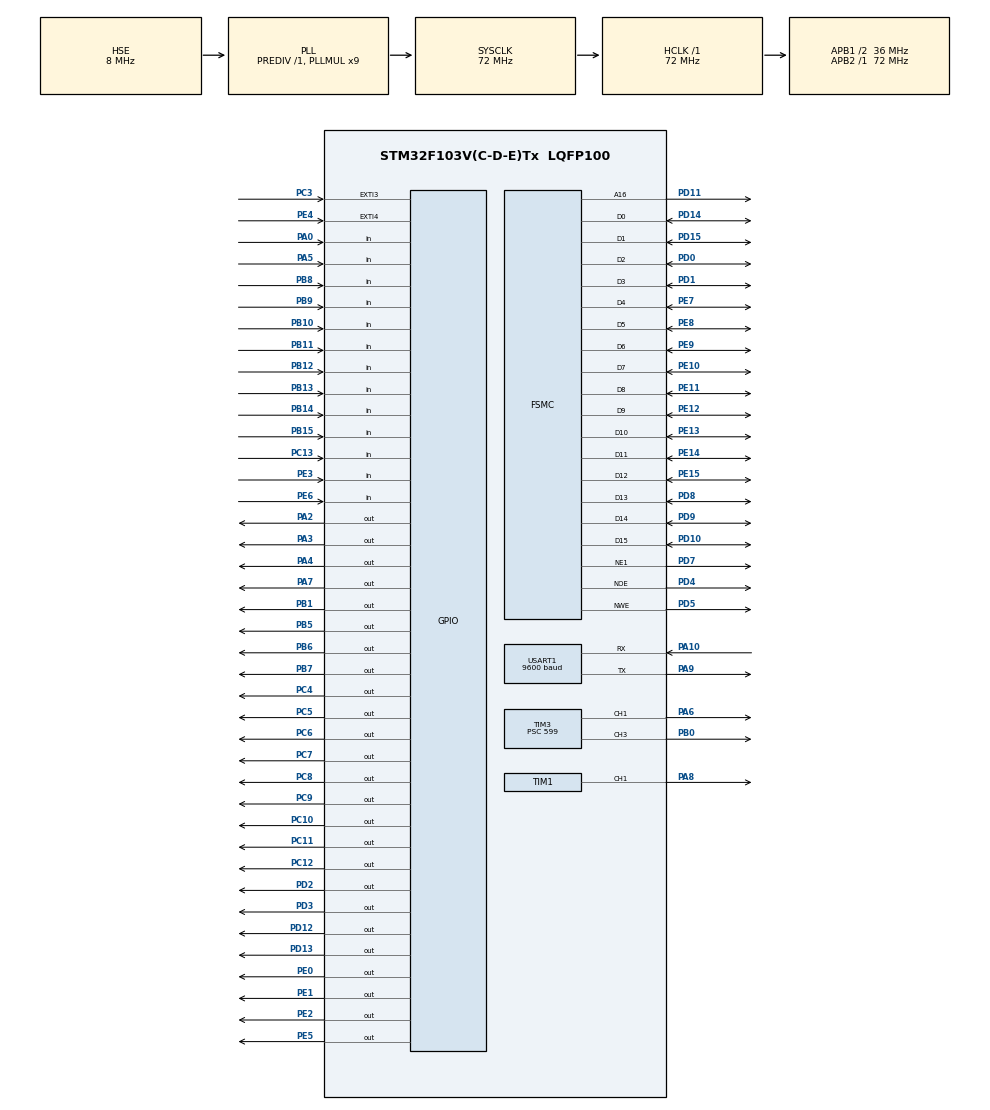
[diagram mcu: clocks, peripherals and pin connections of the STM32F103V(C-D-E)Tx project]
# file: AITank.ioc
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Mcu.Family=STM32F1
Mcu.Name=STM32F103V(C-D-E)Tx
Mcu.Package=LQFP100
NVIC.EXTI3_IRQn=true\:0\:0\:false\:false\:true\:true\:true\:true
NVIC.EXTI4_IRQn=true\:0\:0\:false\:false\:true\:true\:true\:true
NVIC.PriorityGroup=NVIC_PRIORITYGROUP_4
NVIC.TIM2_IRQn=true\:0\:0\:false\:false\:true\:true\:true\:true
OSC_IN.Mode=HSE-External-Oscillator
OSC_IN.Signal=RCC_OSC_IN
OSC_OUT.Mode=HSE-External-Oscillator
OSC_OUT.Signal=RCC_OSC_OUT
PA0-WKUP.Signal=GPIO_Input
PA10.Mode=Asynchronous
PA10.Signal=USART1_RX
PA13.Mode=Serial_Wire
PA13.Signal=SYS_JTMS-SWDIO
PA14.Mode=Serial_Wire
PA14.Signal=SYS_JTCK-SWCLK
PA2.GPIO_Speed=GPIO_SPEED_FREQ_HIGH
PA2.Signal=GPIO_Output
PA3.GPIO_Speed=GPIO_SPEED_FREQ_HIGH
PA3.Signal=GPIO_Output
PA4.GPIO_Speed=GPIO_SPEED_FREQ_HIGH
PA4.PinState=GPIO_PIN_RESET
PA4.Signal=GPIO_Output
PA5.Signal=GPIO_Input
PA6.GPIO_Speed=GPIO_SPEED_FREQ_LOW
PA6.Signal=S_TIM3_CH1
PA7.Signal=GPIO_Output
PA8.Signal=S_TIM1_CH1
PA9.Mode=Asynchronous
PA9.Signal=USART1_TX
PB0.Signal=S_TIM3_CH3
PB1.GPIO_Speed=GPIO_SPEED_FREQ_HIGH
PB1.PinState=GPIO_PIN_SET
PB1.Signal=GPIO_Output
PB10.Signal=GPIO_Input
PB11.Signal=GPIO_Input
PB12.Signal=GPIO_Input
PB13.Signal=GPIO_Input
PB14.Signal=GPIO_Input
PB15.Signal=GPIO_Input
PB5.GPIO_Speed=GPIO_SPEED_FREQ_HIGH
PB5.PinState=GPIO_PIN_SET
PB5.Signal=GPIO_Output
PB6.GPIO_Speed=GPIO_SPEED_FREQ_HIGH
PB6.Signal=GPIO_Output
PB7.GPIO_Speed=GPIO_SPEED_FREQ_HIGH
PB7.Signal=GPIO_Output
PB8.Signal=GPIO_Input
PB9.Signal=GPIO_Input
PC10.GPIO_Speed=GPIO_SPEED_FREQ_HIGH
PC10.Signal=GPIO_Output
PC11.GPIO_Speed=GPIO_SPEED_FREQ_HIGH
PC11.Signal=GPIO_Output
PC12.GPIO_Speed=GPIO_SPEED_FREQ_HIGH
PC12.Signal=GPIO_Output
PC13-TAMPER-RTC.Signal=GPIO_Input
PC14-OSC32_IN.Mode=LSE-External-Oscillator
PC14-OSC32_IN.Signal=RCC_OSC32_IN
PC15-OSC32_OUT.Mode=LSE-External-Oscillator
PC15-OSC32_OUT.Signal=RCC_OSC32_OUT
PC3.GPIO_ModeDefaultEXTI=GPIO_MODE_IT_FALLING
PC3.Signal=GPXTI3
PC4.GPIO_Speed=GPIO_SPEED_FREQ_HIGH
PC4.Signal=GPIO_Output
PC5.GPIO_Speed=GPIO_SPEED_FREQ_HIGH
PC5.Signal=GPIO_Output
PC6.GPIO_ModeDefaultOutputPP=GPIO_MODE_OUTPUT_OD
PC6.GPIO_PuPd=GPIO_NOPULL
PC6.GPIO_Speed=GPIO_SPEED_FREQ_HIGH
PC6.Signal=GPIO_Output
PC7.GPIO_ModeDefaultOutputPP=GPIO_MODE_OUTPUT_OD
PC7.GPIO_PuPd=GPIO_NOPULL
PC7.GPIO_Speed=GPIO_SPEED_FREQ_HIGH
PC7.Signal=GPIO_Output
PC8.GPIO_Speed=GPIO_SPEED_FREQ_HIGH
PC8.Signal=GPIO_Output
PC9.GPIO_Speed=GPIO_SPEED_FREQ_HIGH
PC9.Signal=GPIO_Output
PD0.Mode=16b-d1
PD0.Signal=FSMC_D2
PD1.Mode=16b-d1
PD1.Signal=FSMC_D3
PD10.Mode=16b-d1
PD10.Signal=FSMC_D15
PD11.Mode=A16_1
PD11.Signal=FSMC_A16
PD12.GPIO_Speed=GPIO_SPEED_FREQ_HIGH
PD12.Signal=GPIO_Output
PD13.GPIO_Speed=GPIO_SPEED_FREQ_HIGH
PD13.Signal=GPIO_Output
PD14.Mode=16b-d1
PD14.Signal=FSMC_D0
PD15.Mode=16b-d1
PD15.Signal=FSMC_D1
PD2.GPIO_Speed=GPIO_SPEED_FREQ_HIGH
PD2.Signal=GPIO_Output
PD3.GPIO_Speed=GPIO_SPEED_FREQ_HIGH
PD3.Signal=GPIO_Output
PD4.Mode=Lcd1
PD4.Signal=FSMC_NOE
PD5.Mode=Lcd1
PD5.Signal=FSMC_NWE
PD7.Mode=NorPsramChipSelect1_1
PD7.Signal=FSMC_NE1
PD8.Mode=16b-d1
PD8.Signal=FSMC_D13
PD9.Mode=16b-d1
PD9.Signal=FSMC_D14
PE0.GPIO_Speed=GPIO_SPEED_FREQ_HIGH
PE0.Signal=GPIO_Output
PE1.Signal=GPIO_Output
PE10.Mode=16b-d1
PE10.Signal=FSMC_D7
PE11.Mode=16b-d1
PE11.Signal=FSMC_D8
PE12.Mode=16b-d1
PE12.Signal=FSMC_D9
PE13.Mode=16b-d1
PE13.Signal=FSMC_D10
PE14.Mode=16b-d1
PE14.Signal=FSMC_D11
PE15.Mode=16b-d1
PE15.Signal=FSMC_D12
PE2.GPIO_Speed=GPIO_SPEED_FREQ_HIGH
PE2.Signal=GPIO_Output
PE3.GPIO_PuPd=GPIO_PULLUP
PE3.Signal=GPIO_Input
PE4.GPIO_ModeDefaultEXTI=GPIO_MODE_IT_FALLING
PE4.GPIO_PuPd=GPIO_PULLUP
PE4.Signal=GPXTI4
PE5.Signal=GPIO_Output
PE6.Signal=GPIO_Input
PE7.Mode=16b-d1
PE7.Signal=FSMC_D4
PE8.Mode=16b-d1
PE8.Signal=FSMC_D5
PE9.Mode=16b-d1
PE9.Signal=FSMC_D6
ProjectManager.HeapSize=0x200
ProjectManager.StackSize=0x400
ProjectManager.TargetToolchain=STM32CubeIDE
RCC.AHBFreq_Value=72000000
RCC.APB1CLKDivider=RCC_HCLK_DIV2
RCC.APB1Freq_Value=36000000
RCC.APB1TimFreq_Value=72000000
RCC.APB2Freq_Value=72000000
RCC.APB2TimFreq_Value=72000000
RCC.HCLKFreq_Value=72000000
RCC.PLLMUL=RCC_PLL_MUL9
RCC.PLLSourceVirtual=RCC_PLLSOURCE_HSE
RCC.SYSCLKFreq_VALUE=72000000
RCC.SYSCLKSource=RCC_SYSCLKSOURCE_PLLCLK
RCC.USBFreq_Value=72000000
SH.S_TIM1_CH1.0=TIM1_CH1,PWM Generation1 CH1
SH.S_TIM3_CH1.0=TIM3_CH1,PWM Generation1 CH1
SH.S_TIM3_CH3.0=TIM3_CH3,PWM Generation3 CH3
TIM1.Channel-PWM\ Generation1\ CH1=TIM_CHANNEL_1
TIM1.Period=1000-1
TIM1.Prescaler=1400-1
TIM2.Period=57
TIM2.Prescaler=72
TIM2.TIM_MasterOutputTrigger=TIM_TRGO_UPDATE
TIM3.Channel-PWM\ Generation1\ CH1=TIM_CHANNEL_1
TIM3.Channel-PWM\ Generation3\ CH3=TIM_CHANNEL_3
TIM3.Period=1199
TIM3.Prescaler=599
TIM3.Pulse-PWM\ Generation1\ CH1=0
TIM3.TIM_MasterOutputTrigger=TIM_TRGO_RESET
TIM3.TIM_MasterSlaveMode=TIM_MASTERSLAVEMODE_DISABLE
USART1.BaudRate=9600
USART1.VirtualMode=VM_ASYNC
VP_TIM1_VS_ClockSourceINT.Mode=Internal
VP_TIM2_VS_ClockSourceINT.Mode=Internal
VP_TIM3_VS_ClockSourceINT.Mode=Internal
board=custom

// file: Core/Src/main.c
/* USER CODE BEGIN Header */
/**
  ******************************************************************************
  * @file           : main.c
  * @brief          : Main program body
  ******************************************************************************
  * @attention
  *
  * Copyright (c) 2023 STMicroelectronics.
  * All rights reserved.
  *
  * This software is licensed under terms that can be found in the LICENSE file
  * in the root directory of this software component.
  * If no LICENSE file comes with this software, it is provided AS-IS.
  *
  ******************************************************************************
  */
/* USER CODE END Header */
#include "main.h"

/* USER CODE BEGIN Includes */
#include "lcdtp.h"
#include <string.h>
#include "bsp_ov7725.h"
#include "bsp_sccb.h"
/* USER CODE END Includes */

 TIM_HandleTypeDef htim1;
TIM_HandleTypeDef htim2;
TIM_HandleTypeDef htim3;

UART_HandleTypeDef huart1;

SRAM_HandleTypeDef hsram1;

/* USER CODE BEGIN PV */
//for ultrasonic sensors
bool interruptTrigger = false;
volatile uint16_t distancesInCm[2] = {1000,1000};

//for Bluetooth
uint8_t Rxstr;

//for servo motor rotation
int add = 1, degree = 62;

// for selecting color and shape
uint16_t ColorDisplay4ShapeSelect;
char* ShapeSelected = NULL;
char* ColorSelected = NULL;
int color_picked = 0;
uint16_t obj_coor = 0;
/* USER CODE END PV */

void SystemClock_Config(void);
static void MX_GPIO_Init(void);
static void MX_TIM2_Init(void);
static void MX_FSMC_Init(void);
static void MX_TIM3_Init(void);
static void MX_USART1_UART_Init(void);
static void MX_TIM1_Init(void);
/* USER CODE BEGIN PFP */
volatile uint8_t Ov7725_vsync ;
void direcitonControl(DIRECTION, DIRECTION);
void speedControl(const int, DIRECTION);
void GetColor(void);
void GetShape(void);
void Reset_LCDandLIGHT(void);
void constantrotate(int*,int*);
/* USER CODE END PFP */

int main(void)
{

  /* MCU Configuration--------------------------------------------------------*/

  /* Reset of all peripherals, Initializes the Flash interface and the Systick. */
  HAL_Init();

  /* Configure the system clock */
  SystemClock_Config();

  /* Initialize all configured peripherals */
  MX_GPIO_Init();
  MX_TIM2_Init();
  MX_FSMC_Init();
  MX_TIM3_Init();
  MX_USART1_UART_Init();
  MX_TIM1_Init();
  /* USER CODE BEGIN 2 */
  LCD_INIT();
  macXPT2046_CS_DISABLE(); // for touchpad
  HAL_TIM_PWM_Start(&htim1,TIM_CHANNEL_1);
  HAL_TIM_PWM_Start(&htim3, TIM_CHANNEL_1);
  HAL_TIM_PWM_Start(&htim3, TIM_CHANNEL_3);

// -----------------------------------FOR Color Selection:-------------------------------------------------

  LCD_Clear ( 0, 0, 240, 320, GREY );
  LCD_Clear ( 10,  20,  100, 100, RED	);
  LCD_Clear ( 130,  20,  100, 100, GREEN );
  LCD_Clear ( 10,  200,  100, 100, BLUE );
  LCD_Clear ( 130,  200,  100, 100, BLACK );

  const char* confirm_message = "Press K1 to confirm";
  const char* color_message = "Choose desired color (Black   means disable color function)";
  const char* shape_message = "Choose desired shape (Black   means disable shape function)";

  LCD_DrawString_Color(120 - strlen(color_message)/2*8, 130, color_message, YELLOW, BLACK);
  LCD_DrawString_Color(120 - strlen(confirm_message)/2*8, 304, confirm_message, YELLOW, BLACK);

  while (HAL_GPIO_ReadPin(GPIOA, GPIO_PIN_0) != GPIO_PIN_SET)
  {
	  GetColor();
  }

  Reset_LCDandLIGHT();

// -----------------------------------FOR Shape Selection:-------------------------------------------------
  if (strcmp(ColorSelected, "Red") == 0)
	  ColorDisplay4ShapeSelect = RED;
  else if (strcmp(ColorSelected, "Green") == 0)
	  ColorDisplay4ShapeSelect = GREEN;
  else if (strcmp(ColorSelected, "Blue") == 0)
	  ColorDisplay4ShapeSelect = BLUE;
  else
	  ColorDisplay4ShapeSelect = CYAN;

  LCD_Clear ( 10,  20,  100, 100, ColorDisplay4ShapeSelect );
  LCD_Clear ( 130,  20,  100, 100, ColorDisplay4ShapeSelect );
  LCD_Clear ( 10,  200,  100, 100, ColorDisplay4ShapeSelect );
  LCD_Clear ( 130,  200,  100, 100, BLACK );

  LCD_DrawString_Color(120 - strlen(shape_message)/2*8, 130, shape_message, YELLOW, BLACK);
  LCD_DrawString_Color(120 - strlen(confirm_message)/2*8, 304, confirm_message, YELLOW, BLACK);

  // Drawing triangle
  LCD_DrawLine(60, 30, 13, 110, BLACK);
  LCD_DrawLine(107, 110, 13, 110, BLACK);
  LCD_DrawLine(60, 30, 107, 110, BLACK);

  // Drawing rectangle
  LCD_DrawLine(140, 30, 220, 30, BLACK);
  LCD_DrawLine(220, 110, 220, 30, BLACK);
  LCD_DrawLine(140, 30, 140, 110, BLACK);
  LCD_DrawLine(140, 110, 220, 110, BLACK);

  // Drawing circle
  LCD_DrawCircle(60, 250, 40, BLACK);

  while (HAL_GPIO_ReadPin(GPIOA, GPIO_PIN_0) != GPIO_PIN_SET)
  {
  	  GetShape();
  }
  Reset_LCDandLIGHT();

  __HAL_TIM_SetCompare(&htim1, TIM_CHANNEL_1, degree);

  /* USER CODE END 2 */

  /* Infinite loop */
  /* USER CODE BEGIN WHILE */
  uint16_t i, j, Camera_Data;
  uint8_t Y0;
  uint32_t count1 = 0;
  uint32_t count2 = 0;
  while(Ov7725_Init() != SUCCESS);
  Ov7725_vsync = 0;

  while (1)
  {
    /* USER CODE END WHILE */

    /* USER CODE BEGIN 3 */
	  obj_coor = 0;
	  // for obstacle detection interrupt
	  if (interruptTrigger == true\])
	  {
		  interruptTrigger = false;
		  HAL_Delay(50);
		  directionControl(FORWARD, LEFT);
		  directionControl(FORWARD, RIGHT);
		  speedControl(1000, LEFT);
		  speedControl(1000, RIGHT);
	  }

/*
 *
 * Period is **1200** for car speed PWM control
 * choose speed = 1200 in "speedControl" function to get the maximum speed (100% duty cycle)
 *
 */

//-----------------------------FOR Ultrasonic Sensor:-----------------------------------------------------------

	  sensor = 0; //update sensor index in timer2
	  distancesInCm[0] = measureDistance(triggerPorts[0], triggerPins[0], echoPorts[0], echoPins[0]);
	  sensor = 1; //update sensor index in timer2
	  distancesInCm[1] = measureDistance(triggerPorts[1], triggerPins[1], echoPorts[1], echoPins[1]);

//-------------------------------FOR Bluetooth:--------------------------------------------------------

	  if (HAL_UART_Receive(&huart1,&Rxstr,1,100) == HAL_OK)
	  {
	  	  	  if (Rxstr == 0x01)
	  	  	  {     //left
	  	  	  		directionControl(FORWARD, RIGHT);
	  	  	  		speedControl(1000, RIGHT);
	  	  	  	    directionControl(BACKWARD, LEFT);
	  	  	  	    speedControl(600, LEFT);

	  	  	  }

	  	  	  else if (Rxstr == 0x02)
	  	  	  {     //right
	  	            directionControl(BACKWARD, RIGHT);
	  	            speedControl(600, RIGHT);
	  	  			directionControl(FORWARD, LEFT);
	  	  			speedControl(1000, LEFT);
	  	  		    HAL_GPIO_WritePin(GPIOB, GPIO_PIN_0, GPIO_PIN_RESET);
	  	  	  }

	  	  	  else if (Rxstr == 0x03)
	  	  	  {     //start
	  	  		    directionControl(FORWARD, LEFT);
	  	  		    directionControl(FORWARD, RIGHT);
	  	  		    speedControl(1000, LEFT);
	  	  		    speedControl(1000, RIGHT);

	  	  	  }

	  	  	  else if (Rxstr == 0x04)
	  	  	  {     //stop
	  	  		  	directionControl(STOP, NONE);
	  	  		    HAL_GPIO_WritePin(GPIOB, GPIO_PIN_1, GPIO_PIN_RESET);
	  	  	  }

	  	  	  else if (Rxstr == 0x05)
	  	  	  {     //nothing
	  	  		    directionControl(FORWARD, LEFT);
	  	  			directionControl(FORWARD, RIGHT);
	  	  			speedControl(1000, LEFT);
	  	  			speedControl(1000, RIGHT);
	  	  		    HAL_GPIO_WritePin(GPIOB, GPIO_PIN_1, GPIO_PIN_SET);
	  	  		    HAL_GPIO_WritePin(GPIOB, GPIO_PIN_5, GPIO_PIN_SET);
	  	  	  }
	  }

	  // ----------------------------------------FOR Color and Shape detection:------------------------------------------------------

	  if(ColorSelected != NULL)
	  {
		  if (Ov7725_vsync == 2)
	  	  {
	  	  	  	FIFO_PREPARE;
	  	  	  	obj_coor = ColorDetect();
	  	  	  	Ov7725_vsync = 0;
	  	  }
	  }

	  else if(ShapeSelected != NULL)
	  {
		  // -------Finding the shape center---------
		  	    uint8_t blurred_image[100][100]={0};
		  	    uint16_t minx = 400, miny = 400, maxx = 0, maxy = 0;
		        uint32_t center_x = 0, center_y = 0, temp1 = 0, temp2 = 0;
		        uint8_t optT = 160;
		        count1 = 0;
		        count2 = 0;

		        FIFO_PREPARE;
		  	    for(i = 0; i < 240; i++)
		  	    {
		  	        for(j = 0; j < 320; j++)
		  	        {
		  	            READ_FIFO_PIXEL(Camera_Data); // First pixel
		  	            Y0 = ( Camera_Data & 0xFF00 ) >> 8;
		  	            // Otsu's thresholding --> find Optimal threshold
		  	            if (Y0 > 170)
		  	            {
		  	                center_x = (center_x + i); // find center
		  	                center_y = (center_y + j);
		  	                temp1 += Y0;
		  	                count1++;
		  	            }
		  	            else
		  	            {
		  	            	temp2 += Y0;
		  	            	count2++;
		  	            }
		  	        }
		  	    }
		  	    if (count1 > 0)
		  	    {
		  	    	if(count2 > 0)  optT = 0.5*(temp1/count1+temp2/count2); //Otsu's threshold

		  	        center_x /= count1;
		  	        center_y /= count1;
		  	    }

		  	    FIFO_PREPARE;
		  	    for(i = 0; i < 240; i++)
		  	    {
		  	        for(j = 0; j < 320; j++)
		  	        {
		  	            READ_FIFO_PIXEL(Camera_Data); // First pixel
		  	            Y0 = ( Camera_Data & 0xFF00 ) >> 8;
		  	            if(i <= (center_x + 50) && i >= (center_x - 49) && j <= (center_y + 50) && j >= (center_y - 49))
		  	            {   // check in range
		  	            	count1 = i - center_x + 49;
		  	            	count2 = j - center_y + 49;
		  	            	blurred_image[count1][count2] = (Y0 > optT+50) ? Y0 : 0;

		  	            	if(blurred_image[count1][count2] != 0)
		  	            	{
		  	            		if(j > maxy)
		  	            			maxy = j;
		  	            		else if (j < miny)
		  	            			miny = j;
		  						if(i > maxx)
		  							maxx = i;
		  						else if (i < minx)
		  							minx = i;
		  	            	}
		  	            }
		  	        }
		  	    }

		  	    ////////////////////////////////////////////////////////////////////(disp)
		  	    FIFO_PREPARE;
		  	    //   | 319,0               |
		  	    //   |                     |
		  	    //   | 0,0            0,219|
		  	    //ImagDisp_ori();
		  	    //ImagDisp_30_4(center_x, center_y, optT, blurred_image);

		  	    bool isfound = false;
		  	    isfound = ShapeDetect(&center_x, &center_y, optT, blurred_image, &miny, &minx, &maxy, &maxx, &ShapeSelected);
		  	    if (isfound)
		  	    	obj_coor = center_y;

		  	    Ov7725_vsync = 0;
	  }

	  //-------------------------------FOR Servo Motor Rotation:------------------------------------------------------
	  degree += add;
	  if (ColorSelected == NULL && ShapeSelected == NULL)
	  {
		  HAL_Delay(1000);
	  }

	  constantrotate(&degree, &add);

	  if (obj_coor < 170 && obj_coor > 150)
	  {
		  HAL_GPIO_WritePin(GPIOB, GPIO_PIN_5, GPIO_PIN_SET);
		  directionControl(STOP, NONE);
		  HAL_Delay(500);
		  HAL_GPIO_WritePin(GPIOB, GPIO_PIN_5, GPIO_PIN_RESET);
		  HAL_Delay(500);
		  HAL_GPIO_WritePin(GPIOB, GPIO_PIN_5, GPIO_PIN_SET);
		  HAL_Delay(500);
		  HAL_GPIO_WritePin(GPIOB, GPIO_PIN_5, GPIO_PIN_RESET);
		  HAL_Delay(500);
		  HAL_GPIO_WritePin(GPIOB, GPIO_PIN_5, GPIO_PIN_SET);
		  HAL_Delay(1000);
		  directionControl(FORWARD, LEFT);
		  directionControl(FORWARD, RIGHT);
		  speedControl(1000, LEFT);
		  speedControl(1000, RIGHT);
		  obj_coor = 0;
	  }
  }
  /* USER CODE END 3 */
}

void SystemClock_Config(void)
{
  RCC_OscInitTypeDef RCC_OscInitStruct = {0};
  RCC_ClkInitTypeDef RCC_ClkInitStruct = {0};

  /** Initializes the RCC Oscillators according to the specified parameters
  * in the RCC_OscInitTypeDef structure.
  */
  RCC_OscInitStruct.OscillatorType = RCC_OSCILLATORTYPE_HSE;
  RCC_OscInitStruct.HSEState = RCC_HSE_ON;
  RCC_OscInitStruct.HSEPredivValue = RCC_HSE_PREDIV_DIV1;
  RCC_OscInitStruct.HSIState = RCC_HSI_ON;
  RCC_OscInitStruct.PLL.PLLState = RCC_PLL_ON;
  RCC_OscInitStruct.PLL.PLLSource = RCC_PLLSOURCE_HSE;
  RCC_OscInitStruct.PLL.PLLMUL = RCC_PLL_MUL9;
  if (HAL_RCC_OscConfig(&RCC_OscInitStruct) != HAL_OK)
  {
    Error_Handler();
  }

  /** Initializes the CPU, AHB and APB buses clocks
  */
  RCC_ClkInitStruct.ClockType = RCC_CLOCKTYPE_HCLK|RCC_CLOCKTYPE_SYSCLK
                              |RCC_CLOCKTYPE_PCLK1|RCC_CLOCKTYPE_PCLK2;
  RCC_ClkInitStruct.SYSCLKSource = RCC_SYSCLKSOURCE_PLLCLK;
  RCC_ClkInitStruct.AHBCLKDivider = RCC_SYSCLK_DIV1;
  RCC_ClkInitStruct.APB1CLKDivider = RCC_HCLK_DIV2;
  RCC_ClkInitStruct.APB2CLKDivider = RCC_HCLK_DIV1;

  if (HAL_RCC_ClockConfig(&RCC_ClkInitStruct, FLASH_LATENCY_2) != HAL_OK)
  {
    Error_Handler();
  }
}

static void MX_TIM1_Init(void)
{

  TIM_ClockConfigTypeDef sClockSourceConfig = {0};
  TIM_MasterConfigTypeDef sMasterConfig = {0};
  TIM_OC_InitTypeDef sConfigOC = {0};
  TIM_BreakDeadTimeConfigTypeDef sBreakDeadTimeConfig = {0};

  htim1.Instance = TIM1;
  htim1.Init.Prescaler = 1400-1;
  htim1.Init.CounterMode = TIM_COUNTERMODE_UP;
  htim1.Init.Period = 1000-1;
  htim1.Init.ClockDivision = TIM_CLOCKDIVISION_DIV1;
  htim1.Init.RepetitionCounter = 0;
  htim1.Init.AutoReloadPreload = TIM_AUTORELOAD_PRELOAD_DISABLE;
  if (HAL_TIM_Base_Init(&htim1) != HAL_OK)
  {
    Error_Handler();
  }
  sClockSourceConfig.ClockSource = TIM_CLOCKSOURCE_INTERNAL;
  if (HAL_TIM_ConfigClockSource(&htim1, &sClockSourceConfig) != HAL_OK)
  {
    Error_Handler();
  }
  if (HAL_TIM_PWM_Init(&htim1) != HAL_OK)
  {
    Error_Handler();
  }
  sMasterConfig.MasterOutputTrigger = TIM_TRGO_RESET;
  sMasterConfig.MasterSlaveMode = TIM_MASTERSLAVEMODE_DISABLE;
  if (HAL_TIMEx_MasterConfigSynchronization(&htim1, &sMasterConfig) != HAL_OK)
  {
    Error_Handler();
  }
  sConfigOC.OCMode = TIM_OCMODE_PWM1;
  sConfigOC.Pulse = 0;
  sConfigOC.OCPolarity = TIM_OCPOLARITY_HIGH;
  sConfigOC.OCNPolarity = TIM_OCNPOLARITY_HIGH;
  sConfigOC.OCFastMode = TIM_OCFAST_DISABLE;
  sConfigOC.OCIdleState = TIM_OCIDLESTATE_RESET;
  sConfigOC.OCNIdleState = TIM_OCNIDLESTATE_RESET;
  if (HAL_TIM_PWM_ConfigChannel(&htim1, &sConfigOC, TIM_CHANNEL_1) != HAL_OK)
  {
    Error_Handler();
  }
  sBreakDeadTimeConfig.OffStateRunMode = TIM_OSSR_DISABLE;
  sBreakDeadTimeConfig.OffStateIDLEMode = TIM_OSSI_DISABLE;
  sBreakDeadTimeConfig.LockLevel = TIM_LOCKLEVEL_OFF;
  sBreakDeadTimeConfig.DeadTime = 0;
  sBreakDeadTimeConfig.BreakState = TIM_BREAK_DISABLE;
  sBreakDeadTimeConfig.BreakPolarity = TIM_BREAKPOLARITY_HIGH;
  sBreakDeadTimeConfig.AutomaticOutput = TIM_AUTOMATICOUTPUT_DISABLE;
  if (HAL_TIMEx_ConfigBreakDeadTime(&htim1, &sBreakDeadTimeConfig) != HAL_OK)
  {
    Error_Handler();
  }
  HAL_TIM_MspPostInit(&htim1);

}

static void MX_TIM2_Init(void)
{

  TIM_ClockConfigTypeDef sClockSourceConfig = {0};
  TIM_MasterConfigTypeDef sMasterConfig = {0};

  htim2.Instance = TIM2;
  htim2.Init.Prescaler = 72;
  htim2.Init.CounterMode = TIM_COUNTERMODE_UP;
  htim2.Init.Period = 57;
  htim2.Init.ClockDivision = TIM_CLOCKDIVISION_DIV1;
  htim2.Init.AutoReloadPreload = TIM_AUTORELOAD_PRELOAD_DISABLE;
  if (HAL_TIM_Base_Init(&htim2) != HAL_OK)
  {
    Error_Handler();
  }
  sClockSourceConfig.ClockSource = TIM_CLOCKSOURCE_INTERNAL;
  if (HAL_TIM_ConfigClockSource(&htim2, &sClockSourceConfig) != HAL_OK)
  {
    Error_Handler();
  }
  sMasterConfig.MasterOutputTrigger = TIM_TRGO_UPDATE;
  sMasterConfig.MasterSlaveMode = TIM_MASTERSLAVEMODE_DISABLE;
  if (HAL_TIMEx_MasterConfigSynchronization(&htim2, &sMasterConfig) != HAL_OK)
  {
    Error_Handler();
  }

}

static void MX_TIM3_Init(void)
{

  TIM_ClockConfigTypeDef sClockSourceConfig = {0};
  TIM_MasterConfigTypeDef sMasterConfig = {0};
  TIM_OC_InitTypeDef sConfigOC = {0};

  htim3.Instance = TIM3;
  htim3.Init.Prescaler = 599;
  htim3.Init.CounterMode = TIM_COUNTERMODE_UP;
  htim3.Init.Period = 1199;
  htim3.Init.ClockDivision = TIM_CLOCKDIVISION_DIV1;
  htim3.Init.AutoReloadPreload = TIM_AUTORELOAD_PRELOAD_DISABLE;
  if (HAL_TIM_Base_Init(&htim3) != HAL_OK)
  {
    Error_Handler();
  }
  sClockSourceConfig.ClockSource = TIM_CLOCKSOURCE_INTERNAL;
  if (HAL_TIM_ConfigClockSource(&htim3, &sClockSourceConfig) != HAL_OK)
  {
    Error_Handler();
  }
  if (HAL_TIM_PWM_Init(&htim3) != HAL_OK)
  {
    Error_Handler();
  }
  sMasterConfig.MasterOutputTrigger = TIM_TRGO_RESET;
  sMasterConfig.MasterSlaveMode = TIM_MASTERSLAVEMODE_DISABLE;
  if (HAL_TIMEx_MasterConfigSynchronization(&htim3, &sMasterConfig) != HAL_OK)
  {
    Error_Handler();
  }
  sConfigOC.OCMode = TIM_OCMODE_PWM1;
  sConfigOC.Pulse = 0;
  sConfigOC.OCPolarity = TIM_OCPOLARITY_HIGH;
  sConfigOC.OCFastMode = TIM_OCFAST_DISABLE;
  if (HAL_TIM_PWM_ConfigChannel(&htim3, &sConfigOC, TIM_CHANNEL_1) != HAL_OK)
  {
    Error_Handler();
  }
  if (HAL_TIM_PWM_ConfigChannel(&htim3, &sConfigOC, TIM_CHANNEL_3) != HAL_OK)
  {
    Error_Handler();
  }
  HAL_TIM_MspPostInit(&htim3);

}

static void MX_USART1_UART_Init(void)
{

  huart1.Instance = USART1;
  huart1.Init.BaudRate = 9600;
  huart1.Init.WordLength = UART_WORDLENGTH_8B;
  huart1.Init.StopBits = UART_STOPBITS_1;
  huart1.Init.Parity = UART_PARITY_NONE;
  huart1.Init.Mode = UART_MODE_TX_RX;
  huart1.Init.HwFlowCtl = UART_HWCONTROL_NONE;
  huart1.Init.OverSampling = UART_OVERSAMPLING_16;
  if (HAL_UART_Init(&huart1) != HAL_OK)
  {
    Error_Handler();
  }

}

static void MX_GPIO_Init(void)
{
  GPIO_InitTypeDef GPIO_InitStruct = {0};

  /* GPIO Ports Clock Enable */
  __HAL_RCC_GPIOE_CLK_ENABLE();
  __HAL_RCC_GPIOC_CLK_ENABLE();
  __HAL_RCC_GPIOA_CLK_ENABLE();
  __HAL_RCC_GPIOB_CLK_ENABLE();
  __HAL_RCC_GPIOD_CLK_ENABLE();

  /*Configure GPIO pin Output Level */
  HAL_GPIO_WritePin(GPIOE, GPIO_PIN_2|GPIO_PIN_5|GPIO_PIN_0|GPIO_PIN_1, GPIO_PIN_RESET);

  /*Configure GPIO pin Output Level */
  HAL_GPIO_WritePin(GPIOA, GPIO_PIN_2|GPIO_PIN_3|GPIO_PIN_4|GPIO_PIN_7, GPIO_PIN_RESET);

  /*Configure GPIO pin Output Level */
  HAL_GPIO_WritePin(GPIOC, GPIO_PIN_4|GPIO_PIN_5|GPIO_PIN_6|GPIO_PIN_7
                          |GPIO_PIN_8|GPIO_PIN_9|GPIO_PIN_10|GPIO_PIN_11
                          |GPIO_PIN_12, GPIO_PIN_RESET);

  /*Configure GPIO pin Output Level */
  HAL_GPIO_WritePin(GPIOB, GPIO_PIN_1|GPIO_PIN_5, GPIO_PIN_SET);

  /*Configure GPIO pin Output Level */
  HAL_GPIO_WritePin(GPIOD, GPIO_PIN_12|GPIO_PIN_13|GPIO_PIN_2|GPIO_PIN_3, GPIO_PIN_RESET);

  /*Configure GPIO pin Output Level */
  HAL_GPIO_WritePin(GPIOB, GPIO_PIN_6|GPIO_PIN_7, GPIO_PIN_RESET);

  /*Configure GPIO pins : PE2 PE0 */
  GPIO_InitStruct.Pin = GPIO_PIN_2|GPIO_PIN_0;
  GPIO_InitStruct.Mode = GPIO_MODE_OUTPUT_PP;
  GPIO_InitStruct.Pull = GPIO_NOPULL;
  GPIO_InitStruct.Speed = GPIO_SPEED_FREQ_HIGH;
  HAL_GPIO_Init(GPIOE, &GPIO_InitStruct);

  /*Configure GPIO pin : PE3 */
  GPIO_InitStruct.Pin = GPIO_PIN_3;
  GPIO_InitStruct.Mode = GPIO_MODE_INPUT;
  GPIO_InitStruct.Pull = GPIO_PULLUP;
  HAL_GPIO_Init(GPIOE, &GPIO_InitStruct);

  /*Configure GPIO pin : PE4 */
  GPIO_InitStruct.Pin = GPIO_PIN_4;
  GPIO_InitStruct.Mode = GPIO_MODE_IT_FALLING;
  GPIO_InitStruct.Pull = GPIO_PULLUP;
  HAL_GPIO_Init(GPIOE, &GPIO_InitStruct);

  /*Configure GPIO pins : PE5 PE1 */
  GPIO_InitStruct.Pin = GPIO_PIN_5|GPIO_PIN_1;
  GPIO_InitStruct.Mode = GPIO_MODE_OUTPUT_PP;
  GPIO_InitStruct.Pull = GPIO_NOPULL;
  GPIO_InitStruct.Speed = GPIO_SPEED_FREQ_LOW;
  HAL_GPIO_Init(GPIOE, &GPIO_InitStruct);

  /*Configure GPIO pin : PE6 */
  GPIO_InitStruct.Pin = GPIO_PIN_6;
  GPIO_InitStruct.Mode = GPIO_MODE_INPUT;
  GPIO_InitStruct.Pull = GPIO_NOPULL;
  HAL_GPIO_Init(GPIOE, &GPIO_InitStruct);

  /*Configure GPIO pin : PC13 */
  GPIO_InitStruct.Pin = GPIO_PIN_13;
  GPIO_InitStruct.Mode = GPIO_MODE_INPUT;
  GPIO_InitStruct.Pull = GPIO_NOPULL;
  HAL_GPIO_Init(GPIOC, &GPIO_InitStruct);

  /*Configure GPIO pin : PC3 */
  GPIO_InitStruct.Pin = GPIO_PIN_3;
  GPIO_InitStruct.Mode = GPIO_MODE_IT_FALLING;
  GPIO_InitStruct.Pull = GPIO_NOPULL;
  HAL_GPIO_Init(GPIOC, &GPIO_InitStruct);

  /*Configure GPIO pins : PA0 PA5 */
  GPIO_InitStruct.Pin = GPIO_PIN_0|GPIO_PIN_5;
  GPIO_InitStruct.Mode = GPIO_MODE_INPUT;
  GPIO_InitStruct.Pull = GPIO_NOPULL;
  HAL_GPIO_Init(GPIOA, &GPIO_InitStruct);

  /*Configure GPIO pins : PA2 PA3 PA4 */
  GPIO_InitStruct.Pin = GPIO_PIN_2|GPIO_PIN_3|GPIO_PIN_4;
  GPIO_InitStruct.Mode = GPIO_MODE_OUTPUT_PP;
  GPIO_InitStruct.Pull = GPIO_NOPULL;
  GPIO_InitStruct.Speed = GPIO_SPEED_FREQ_HIGH;
  HAL_GPIO_Init(GPIOA, &GPIO_InitStruct);

  /*Configure GPIO pin : PA7 */
  GPIO_InitStruct.Pin = GPIO_PIN_7;
  GPIO_InitStruct.Mode = GPIO_MODE_OUTPUT_PP;
  GPIO_InitStruct.Pull = GPIO_NOPULL;
  GPIO_InitStruct.Speed = GPIO_SPEED_FREQ_LOW;
  HAL_GPIO_Init(GPIOA, &GPIO_InitStruct);

  /*Configure GPIO pins : PC4 PC5 PC8 PC9
                           PC10 PC11 PC12 */
  GPIO_InitStruct.Pin = GPIO_PIN_4|GPIO_PIN_5|GPIO_PIN_8|GPIO_PIN_9
                          |GPIO_PIN_10|GPIO_PIN_11|GPIO_PIN_12;
  GPIO_InitStruct.Mode = GPIO_MODE_OUTPUT_PP;
  GPIO_InitStruct.Pull = GPIO_NOPULL;
  GPIO_InitStruct.Speed = GPIO_SPEED_FREQ_HIGH;
  HAL_GPIO_Init(GPIOC, &GPIO_InitStruct);

  /*Configure GPIO pins : PB1 PB5 PB6 PB7 */
  GPIO_InitStruct.Pin = GPIO_PIN_1|GPIO_PIN_5|GPIO_PIN_6|GPIO_PIN_7;
  GPIO_InitStruct.Mode = GPIO_MODE_OUTPUT_PP;
  GPIO_InitStruct.Pull = GPIO_NOPULL;
  GPIO_InitStruct.Speed = GPIO_SPEED_FREQ_HIGH;
  HAL_GPIO_Init(GPIOB, &GPIO_InitStruct);

  /*Configure GPIO pins : PB10 PB11 PB12 PB13
                           PB14 PB15 PB8 PB9 */
  GPIO_InitStruct.Pin = GPIO_PIN_10|GPIO_PIN_11|GPIO_PIN_12|GPIO_PIN_13
                          |GPIO_PIN_14|GPIO_PIN_15|GPIO_PIN_8|GPIO_PIN_9;
  GPIO_InitStruct.Mode = GPIO_MODE_INPUT;
  GPIO_InitStruct.Pull = GPIO_NOPULL;
  HAL_GPIO_Init(GPIOB, &GPIO_InitStruct);

  /*Configure GPIO pins : PD12 PD13 PD2 PD3 */
  GPIO_InitStruct.Pin = GPIO_PIN_12|GPIO_PIN_13|GPIO_PIN_2|GPIO_PIN_3;
  GPIO_InitStruct.Mode = GPIO_MODE_OUTPUT_PP;
  GPIO_InitStruct.Pull = GPIO_NOPULL;
  GPIO_InitStruct.Speed = GPIO_SPEED_FREQ_HIGH;
  HAL_GPIO_Init(GPIOD, &GPIO_InitStruct);

  /*Configure GPIO pins : PC6 PC7 */
  GPIO_InitStruct.Pin = GPIO_PIN_6|GPIO_PIN_7;
  GPIO_InitStruct.Mode = GPIO_MODE_OUTPUT_OD;
  GPIO_InitStruct.Pull = GPIO_NOPULL;
  GPIO_InitStruct.Speed = GPIO_SPEED_FREQ_HIGH;
  HAL_GPIO_Init(GPIOC, &GPIO_InitStruct);

  /* EXTI interrupt init*/
  HAL_NVIC_SetPriority(EXTI3_IRQn, 0, 0);
  HAL_NVIC_EnableIRQ(EXTI3_IRQn);

  HAL_NVIC_SetPriority(EXTI4_IRQn, 0, 0);
  HAL_NVIC_EnableIRQ(EXTI4_IRQn);

}

/* FSMC initialization function */
static void MX_FSMC_Init(void)
{

  FSMC_NORSRAM_TimingTypeDef Timing = {0};

  /** Perform the SRAM1 memory initialization sequence
  */
  hsram1.Instance = FSMC_NORSRAM_DEVICE;
  hsram1.Extended = FSMC_NORSRAM_EXTENDED_DEVICE;
  /* hsram1.Init */
  hsram1.Init.NSBank = FSMC_NORSRAM_BANK1;
  hsram1.Init.DataAddressMux = FSMC_DATA_ADDRESS_MUX_DISABLE;
  hsram1.Init.MemoryType = FSMC_MEMORY_TYPE_SRAM;
  hsram1.Init.MemoryDataWidth = FSMC_NORSRAM_MEM_BUS_WIDTH_16;
  hsram1.Init.BurstAccessMode = FSMC_BURST_ACCESS_MODE_DISABLE;
  hsram1.Init.WaitSignalPolarity = FSMC_WAIT_SIGNAL_POLARITY_LOW;
  hsram1.Init.WrapMode = FSMC_WRAP_MODE_DISABLE;
  hsram1.Init.WaitSignalActive = FSMC_WAIT_TIMING_BEFORE_WS;
  hsram1.Init.WriteOperation = FSMC_WRITE_OPERATION_ENABLE;
  hsram1.Init.WaitSignal = FSMC_WAIT_SIGNAL_DISABLE;
  hsram1.Init.ExtendedMode = FSMC_EXTENDED_MODE_DISABLE;
  hsram1.Init.AsynchronousWait = FSMC_ASYNCHRONOUS_WAIT_DISABLE;
  hsram1.Init.WriteBurst = FSMC_WRITE_BURST_DISABLE;
  /* Timing */
  Timing.AddressSetupTime = 15;
  Timing.AddressHoldTime = 15;
  Timing.DataSetupTime = 255;
  Timing.BusTurnAroundDuration = 15;
  Timing.CLKDivision = 16;
  Timing.DataLatency = 17;
  Timing.AccessMode = FSMC_ACCESS_MODE_A;
  /* ExtTiming */

  if (HAL_SRAM_Init(&hsram1, &Timing, NULL) != HAL_OK)
  {
    Error_Handler( );
  }

  /** Disconnect NADV
  */

  __HAL_AFIO_FSMCNADV_DISCONNECTED();

}

/* USER CODE BEGIN 4 */
void directionControl(DIRECTION direction, DIRECTION wheel)
{
	if (wheel == LEFT)
	{
		if (direction == FORWARD)
		{
			HAL_GPIO_WritePin(GPIOC, GPIO_PIN_8, GPIO_PIN_SET);
			HAL_GPIO_WritePin(GPIOC, GPIO_PIN_9, GPIO_PIN_RESET);
			HAL_GPIO_WritePin(GPIOC, GPIO_PIN_10, GPIO_PIN_SET);
			HAL_GPIO_WritePin(GPIOC, GPIO_PIN_11, GPIO_PIN_RESET);
		}
		else if (direction == BACKWARD)
		{
			HAL_GPIO_WritePin(GPIOC, GPIO_PIN_8, GPIO_PIN_RESET);
			HAL_GPIO_WritePin(GPIOC, GPIO_PIN_9, GPIO_PIN_SET);
			HAL_GPIO_WritePin(GPIOC, GPIO_PIN_10, GPIO_PIN_RESET);
			HAL_GPIO_WritePin(GPIOC, GPIO_PIN_11, GPIO_PIN_SET);
		}
	}

	else if (wheel == RIGHT)
	{
		if (direction == FORWARD)
		{
			HAL_GPIO_WritePin(GPIOD, GPIO_PIN_2, GPIO_PIN_SET);
			HAL_GPIO_WritePin(GPIOC, GPIO_PIN_12, GPIO_PIN_RESET);
			HAL_GPIO_WritePin(GPIOB, GPIO_PIN_6, GPIO_PIN_SET);
			HAL_GPIO_WritePin(GPIOB, GPIO_PIN_7, GPIO_PIN_RESET);
		}
		else if (direction == BACKWARD)
		{
			HAL_GPIO_WritePin(GPIOD, GPIO_PIN_2, GPIO_PIN_RESET);
			HAL_GPIO_WritePin(GPIOC, GPIO_PIN_12, GPIO_PIN_SET);
			HAL_GPIO_WritePin(GPIOB, GPIO_PIN_6, GPIO_PIN_RESET);
			HAL_GPIO_WritePin(GPIOB, GPIO_PIN_7, GPIO_PIN_SET);
		}
	}
	else if (wheel == NONE)
	{
		if (direction == STOP)
		{
			HAL_GPIO_WritePin(GPIOD, GPIO_PIN_2, GPIO_PIN_RESET);
			HAL_GPIO_WritePin(GPIOC, GPIO_PIN_12, GPIO_PIN_RESET);
			HAL_GPIO_WritePin(GPIOB, GPIO_PIN_6, GPIO_PIN_RESET);
			HAL_GPIO_WritePin(GPIOB, GPIO_PIN_7, GPIO_PIN_RESET);
			HAL_GPIO_WritePin(GPIOC, GPIO_PIN_8, GPIO_PIN_RESET);
			HAL_GPIO_WritePin(GPIOC, GPIO_PIN_9, GPIO_PIN_RESET);
			HAL_GPIO_WritePin(GPIOC, GPIO_PIN_10, GPIO_PIN_RESET);
			HAL_GPIO_WritePin(GPIOC, GPIO_PIN_11, GPIO_PIN_RESET);
		}
	}
}

void speedControl(const int speed, DIRECTION wheel)
{

	if (wheel == LEFT)
		__HAL_TIM_SET_COMPARE(&htim3, TIM_CHANNEL_1, speed-300);
	else if (wheel == RIGHT)
		__HAL_TIM_SET_COMPARE(&htim3, TIM_CHANNEL_3, speed-300);
}

void GetColor(void)
{
	strType_XPT2046_Coordinate strDisplayCoordinate;

	if ( XPT2046_Get_TouchedPoint ( & strDisplayCoordinate, & strXPT2046_TouchPara ) )
	{

		if ( ( strDisplayCoordinate .y > 20 ) && ( strDisplayCoordinate .y < 120 ) )
		{
			// Red
			if ( ( strDisplayCoordinate .x > 10 ) && ( strDisplayCoordinate .x < 110 ) )
			{
				ColorSelected = "Red";
				color_picked = 0;
				HAL_GPIO_WritePin(GPIOB, GPIO_PIN_5, GPIO_PIN_RESET);
				HAL_GPIO_WritePin(GPIOB, GPIO_PIN_0, GPIO_PIN_SET);
				HAL_GPIO_WritePin(GPIOB, GPIO_PIN_1, GPIO_PIN_SET);
			}
			// Green
			else if ( ( strDisplayCoordinate .x > 130 ) && ( strDisplayCoordinate .x < 230 ) )
			{
				ColorSelected = "Green";
				color_picked = 1;
				HAL_GPIO_WritePin(GPIOB, GPIO_PIN_5, GPIO_PIN_SET);
				HAL_GPIO_WritePin(GPIOB, GPIO_PIN_0, GPIO_PIN_RESET);
				HAL_GPIO_WritePin(GPIOB, GPIO_PIN_1, GPIO_PIN_SET);
			}
		}
		else if ( ( strDisplayCoordinate .y > 200 ) && ( strDisplayCoordinate .y < 300 ) )
		{
			// Blue
			if ( ( strDisplayCoordinate .x > 12 ) && ( strDisplayCoordinate .x < 112 ) )
			{
				ColorSelected = "Blue";
				color_picked = 2;
				HAL_GPIO_WritePin(GPIOB, GPIO_PIN_5, GPIO_PIN_SET);
				HAL_GPIO_WritePin(GPIOB, GPIO_PIN_0, GPIO_PIN_SET);
				HAL_GPIO_WritePin(GPIOB, GPIO_PIN_1, GPIO_PIN_RESET);
			}
			// None (White)
			else if ( ( strDisplayCoordinate .x > 130 ) && ( strDisplayCoordinate .x < 230 ) )
			{
				ColorSelected = NULL;

				HAL_GPIO_WritePin(GPIOB, GPIO_PIN_5, GPIO_PIN_RESET);
				HAL_GPIO_WritePin(GPIOB, GPIO_PIN_0, GPIO_PIN_RESET);
				HAL_GPIO_WritePin(GPIOB, GPIO_PIN_1, GPIO_PIN_RESET);
			}
		}
	}
}

void GetShape(void)
{
	strType_XPT2046_Coordinate strDisplayCoordinate;

	if ( XPT2046_Get_TouchedPoint ( & strDisplayCoordinate, & strXPT2046_TouchPara ) )
	{
		if ( ( strDisplayCoordinate .y > 32 ) && ( strDisplayCoordinate .y < 132 ) )
		{
			// Red
			if ( ( strDisplayCoordinate .x > 12 ) && ( strDisplayCoordinate .x < 112 ) )
			{
				ShapeSelected = "Triangle"; // "Triangle", "Square", "Circle"
				HAL_GPIO_WritePin(GPIOB, GPIO_PIN_5, GPIO_PIN_RESET);
				HAL_GPIO_WritePin(GPIOB, GPIO_PIN_0, GPIO_PIN_SET);
				HAL_GPIO_WritePin(GPIOB, GPIO_PIN_1, GPIO_PIN_SET);
			}
			// Green
			else if ( ( strDisplayCoordinate .x > 132 ) && ( strDisplayCoordinate .x < 232 ) )
			{
				ShapeSelected = "Square";
				HAL_GPIO_WritePin(GPIOB, GPIO_PIN_5, GPIO_PIN_SET);
				HAL_GPIO_WritePin(GPIOB, GPIO_PIN_0, GPIO_PIN_RESET);
				HAL_GPIO_WritePin(GPIOB, GPIO_PIN_1, GPIO_PIN_SET);
			}
		}
		else if ( ( strDisplayCoordinate .y > 192 ) && ( strDisplayCoordinate .y < 292 ) )
		{
			// Blue
			if ( ( strDisplayCoordinate .x > 12 ) && ( strDisplayCoordinate .x < 112 ) )
			{
				ShapeSelected = "Circle";
				HAL_GPIO_WritePin(GPIOB, GPIO_PIN_5, GPIO_PIN_SET);
				HAL_GPIO_WritePin(GPIOB, GPIO_PIN_0, GPIO_PIN_SET);
				HAL_GPIO_WritePin(GPIOB, GPIO_PIN_1, GPIO_PIN_RESET);
			}
			// None (White)
			else if ( ( strDisplayCoordinate .x > 132 ) && ( strDisplayCoordinate .x < 232 ) )
			{
				ShapeSelected = NULL;
				HAL_GPIO_WritePin(GPIOB, GPIO_PIN_5, GPIO_PIN_RESET);
				HAL_GPIO_WritePin(GPIOB, GPIO_PIN_0, GPIO_PIN_RESET);
				HAL_GPIO_WritePin(GPIOB, GPIO_PIN_1, GPIO_PIN_RESET);
			}
		}
	}
}

void Reset_LCDandLIGHT(void)
{
	LCD_Clear ( 0, 0, 240, 320, WHITE );
	HAL_GPIO_WritePin(GPIOB, GPIO_PIN_5, GPIO_PIN_SET);
	HAL_GPIO_WritePin(GPIOB, GPIO_PIN_0, GPIO_PIN_SET);
	HAL_GPIO_WritePin(GPIOB, GPIO_PIN_1, GPIO_PIN_SET);
}
void constantrotate(int *i, int *add){
	// red :5v, brown: gnd, yellow:pa8

	//range: 25-125
	__HAL_TIM_SetCompare(&htim1, TIM_CHANNEL_1, *i);

	if (*i == 77)  *add =-1;

	else if (*i == 47 )  *add = 1;
}
/* USER CODE END 4 */

void Error_Handler(void)
{
  __disable_irq();
  while (1)
  {
  }
}
